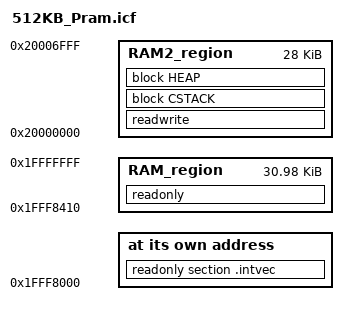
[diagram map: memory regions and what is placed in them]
/*###ICF### Section handled by ICF editor, don't touch! ****/
/*-Editor annotation file-*/
/* IcfEditorFile="$TOOLKIT_DIR$\config\ide\IcfEditor\cortex_v1_0.xml" */
/*-Specials-*/
define symbol __ICFEDIT_intvec_start__ = 0x1FFF8000;
/*-Memory Regions-*/
define symbol __ICFEDIT_region_RAM_start__ = 0x1FFF8410;
define symbol __ICFEDIT_region_RAM_end__   = 0x1FFFFFFF;
/*-Sizes-*/
define symbol __ICFEDIT_size_cstack__ = 0x400;
define symbol __ICFEDIT_size_heap__   = 0x400;
/**** End of ICF editor section. ###ICF###*/

define symbol __ICFEDIT_region_RAM2_start__ = 0x20000000;
define symbol __ICFEDIT_region_RAM2_end__ = 0x20006FFF;

define exported symbol __VECTOR_TABLE = 0x1FFF8000;

define exported symbol __BOOT_STACK_ADDRESS = __ICFEDIT_region_RAM2_end__;
define exported symbol __StackLimit = __BOOT_STACK_ADDRESS-__ICFEDIT_size_cstack__+1;

define memory mem with size = 4G;
define region RAM_region   = mem:[from __ICFEDIT_region_RAM_start__ to  __ICFEDIT_region_RAM_end__];
define region RAM2_region  = mem:[from __ICFEDIT_region_RAM2_start__ to __ICFEDIT_region_RAM2_end__];

define block CSTACK    with alignment = 8, size = __ICFEDIT_size_cstack__   { };
define block HEAP      with alignment = 8, size = __ICFEDIT_size_heap__     { };

initialize by copy { readwrite };
do not initialize  { section .noinit };

place at address mem:__ICFEDIT_intvec_start__ { readonly section .intvec };

place in RAM_region    { readonly };
place in RAM2_region   { readwrite, block CSTACK, block HEAP };
